# IND83212 register map
Series: Verne; File version: B0
CPU: CM0 r0p1, selectable endian, no MPU, no FPU, 4 interrupt priority bits
Registers are 32-bit, read-write, no defined reset value unless marked. A register's access mark holds for its fields unless they carry their own. Offsets are from the block's base; [hi:lo] are bit positions.

## SAR_CTRL — SAR ADC Interface registers
Base 0x50010D00; register names take the prefix SAR_CTRL_
0x00 DATA1 — Data Out of CH1,
  [15:0] DATA1 ro — The result of ADC conversion of CH1(in 2's-complement)
0x04 DATA2 — Data Out of CH2,
  [15:0] DATA2 ro — The result of ADC conversion of CH2(in 2's-complement)
0x08 DATA3 — Data Out of CH3,
  [15:0] DATA3 ro — The result of ADC conversion of CH3(in 2's-complement)
0x0C DATA4 — Data Out of CH4,
  [15:0] DATA4 ro — The result of ADC conversion of CH4(in 2's-complement)
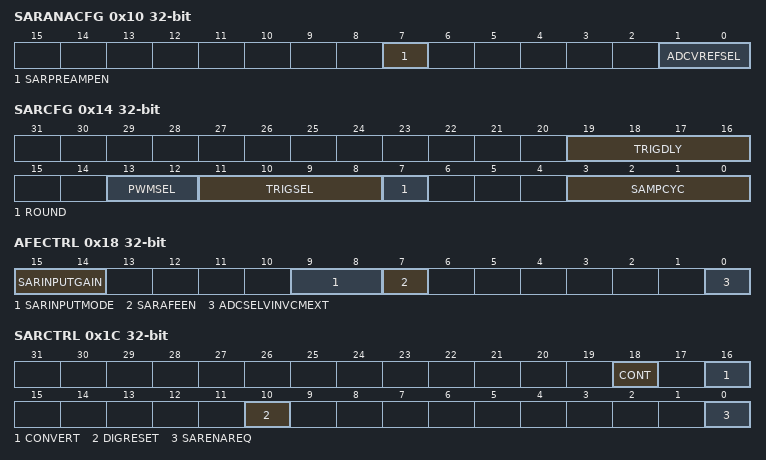
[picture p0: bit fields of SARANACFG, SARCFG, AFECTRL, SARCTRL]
0x10 SARANACFG — SAR Analog Configuration Register
  [7] SARPREAMPEN — adc pre-amp enable. 0:disable, 1:enable
  [1:0] ADCVREFSEL — adc vref select. 0x0: adc_vref = vbg when sar_ena_req=1 0x1: adc_vref = 2*vbg when sar_ena_req=1 0x2: adc_vref = VDD_3V3 when sar_ena_req=1 0x3: adc_vref = VDD_3V3 when sar_ena_req=1
0x14 SARCFG — SAR Configuration Register
  [19:16] TRIGDLY — trigger delay. setting trigger delay time from 0 to 15 sar clock cycles. For PN-detect, trigger delay MUST >= 2us.
  [13:12] PWMSEL — PWM Trigger Signal Selects. Selects the source PWM channel.
  [11:8] TRIGSEL — SAR Converion Trigger Selects. Selects the trigger condition of SAR ADC. Don't change the bits during an ADC conversion sequence is ongoing. 0x1: Triggered through writing 1 to conversion bit. 0x2: Triggered by the PWM posedge. 0x4: Triggered by the PWM negedge. 0x8: Triggered by PWM period.
  [7] ROUND — ADC round enable. Enable ADC round. 0x0: No round. 0x1: Negative code+1
  [3:0] SAMPCYC — Sample cycle. setting sampling time from 1 to 16 sar clock cycles. 0x0: 1 Cycle 0x1: 2 Cycle 0x2: 3 Cycle 0xf: 16 Cycle
0x18 AFECTRL — SAR AFE Control
  [15:14] SARINPUTGAIN — choose ADC input gain. 0x0: 22/32 0x1: 31/32
  [9:8] SARINPUTMODE — ADC AFE Input Modes. Select ADC AFE Input Modes. 0x0: All external. 0x1: VINP buffered, VINN external. 0x2: VINN buffered, VINP external. 0x3: Both VINP & VINN buffered.
  [7] SARAFEEN — ADC AFE Enable. adc afe enable. If vinp, vinn and vin vcm all choose external, adc afe should be disabled: adc_adc_en=0, otherwise, adc afe must be enabled: adc_afe_en=1.
  [0] ADCSELVINVCMEXT — Select External Inputs to ADC. choose ADC input common voltage. 0: choose internal vin_vcm, equals to (vinp+vinn)/2; 1: choose external vin_vcm, for PN detect.
0x1C SARCTRL — SAR ADC Control
  [18] CONT — Continuous Conversion Enable. If this bit has been set before an ADC conversion sequence trigged by CONVERT bit or PWM signals, the sequence will be treated as a sequential conversion, rather than a single conversion.
  [16] CONVERT dual — ADC START/STATUS Register. If SOFTWARE trigger source is selected, set to start a conversion, If SARBAUD trigger source is selected, set to activate the internal baud generator. The tick of the buad generator will trigger an ADC conversion. Read 1 indicates ADC conversion is active; Read 0 indicates ADC is in idle state.
  [10] DIGRESET wo — SAR Digital Part Reset. Resets SAR digital parts. Autoclear: includes a synchronous reset signal which clears the register on the cycle following write.
  [0] SARENAREQ — SAR ADC Enable. Set to enable the SAR analog & digital part
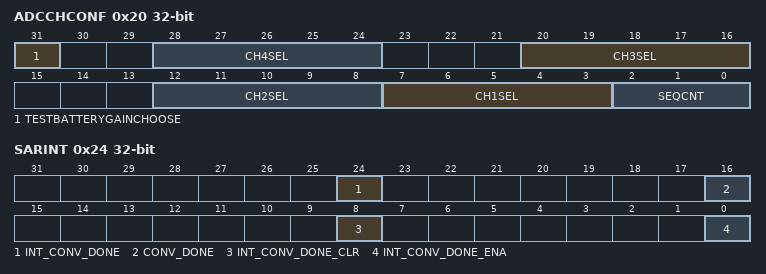
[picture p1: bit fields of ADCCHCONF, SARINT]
0x20 ADCCHCONF — ADC Channel Configuration
  [31] TESTBATTERYGAINCHOOSE — VBAT Gain Select. 0: gain=1/14, vbat max 30V/14=2.14v, under ADC vref=2.4v 1: gain=1/28, vbat max 30V/28=1.07v, under ADC vref=1.2v
  [28:24] CH4SEL — Channel4 Selection. Refer to Channel1 Selects.
  [20:16] CH3SEL — Channel3 Selection. Refer to Channel1 Selects.
  [12:8] CH2SEL — Channel2 Selection. Refer to Channel1 Selects.
  [7:3] CH1SEL — Channel1 Selection. Channel1 Selects. 0x1: adc_vinp=adc_refp , adc_vinn=adc_refp (all shot to adc_ref(2.4V) for adc channel offset K) 0x2: adc_vinp=adc_refp , adc_vinn=vref_gnd (for adc channel +gain error K) 0x3: adc_vinp=vref_gnd , adc_vinn=adc_refp (for adc channel -gain error K) 0x4: adc_vinp=TempSensor , adc_vinn=vref_gnd 0x5: adc_vinp=VDD_1V5 , adc_vinn=vref_gnd 0x6: adc_vinp=VDD_3V3 , adc_vinn=vref_gnd 0x7: adc_vinp=VDD_PRE5V (1/4) , adc_vinn=vref_gnd 0x8: adc_vinp=VBAT ACCURATE (gain selected by TEST_BATTERY_GAIN_CHOOSE), adc_vinn=vref_gnd 0x9: adc_vinp=LED0 , adc_vinn=vref_gnd 0xa: adc_vinp=LED1 , adc_vinn=vref_gnd 0xb: adc_vinp=LED2 , adc_vinn=vref_gnd 0xc: adc_vinp=GPIO1 , adc_vinn=vref_gnd 0xd: adc_vinp=GPIO2 , adc_vinn=vref_gnd 0xe: adc_vinp=GPIO3 , adc_vinn=vref_gnd 0xf: adc_vinp=GPIO4 , adc_vinn=vref_gnd 0x10: adc_vinp=VBAT , adc_vinn=LED0 (with gain selected by ioctrla.LED.GAIN_SEL) 0x11: adc_vinp=VBAT , adc_vinn=LED1 (with gain selected by ioctrla.LED.GAIN_SEL) 0x12: adc_vinp=VBAT , adc_vinn=LED2 (with gain selected by ioctrla.LED.GAIN_SEL)
  [2:0] SEQCNT — Channel Sequence count. Selects the sequence of channels to be converted 0x1: CH1 only 0x2: CH1->CH2 0x3: CH1->CH2->CH3 0x4: CH1->CH2->CH3->CH4
0x24 SARINT — Update
  [24] INT_CONV_DONE ro — Convert Done Interrupt. Set by the SAR when an convert done occurs
  [16] CONV_DONE ro — Convert Done. Set by the SAR when an conversion is done.
  [8] INT_CONV_DONE_CLR wo — Convert Done Interrupt Clear. Autoclear: includes a synchronous reset signal which clears the register on the cycle following write.
  [0] INT_CONV_DONE_ENA — Convert Done Interrupt Enable.
0x28 SARCLKDIV — SAR CLOCK DIVIDE
  [7:0] SARCLKDIV — SAR CLOCK DIVIDE.
